# TM4C129ENCPDT register map
File version: 1.0
CPU: CORTEX_M4 1.0, other endian, MPU, FPU, 3 interrupt priority bits
Registers are 32-bit, read-write, reset 0x0 unless marked. A register's access mark holds for its fields unless they carry their own. Offsets are from the block's base; [hi:lo] are bit positions; {n}, {i} and the like mark numbered series.

## EMAC0 — EMAC register offsets
Base 0x400EC000
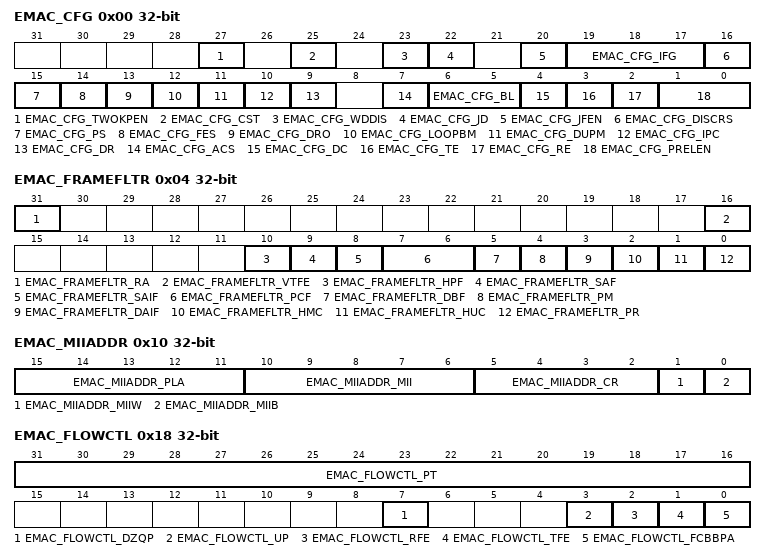
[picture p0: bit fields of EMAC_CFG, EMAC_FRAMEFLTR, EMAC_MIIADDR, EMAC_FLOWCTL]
0x00 EMAC_CFG — Ethernet MAC Configuration
  [27] EMAC_CFG_TWOKPEN — [27:27] IEEE 802
  [25] EMAC_CFG_CST — [25:25] CRC Stripping for Type Frames
  [23] EMAC_CFG_WDDIS — [23:23] Watchdog Disable
  [22] EMAC_CFG_JD — [22:22] Jabber Disable
  [20] EMAC_CFG_JFEN — [20:20] Jumbo Frame Enable
  [19:17] EMAC_CFG_IFG — [19:17] Inter-Frame Gap (IFG)
    0=96 bit times; 0x20000=88 bit times; 0x40000=80 bit times; 0x60000=72 bit times; 0x80000=64 bit times; 0xA0000=56 bit times; 0xC0000=48 bit times; 0xE0000=40 bit times
  [16] EMAC_CFG_DISCRS — [16:16] Disable Carrier Sense During Transmission
  [15] EMAC_CFG_PS — [15:15] Port Select
  [14] EMAC_CFG_FES — [14:14] Speed
  [13] EMAC_CFG_DRO — [13:13] Disable Receive Own
  [12] EMAC_CFG_LOOPBM — [12:12] Loopback Mode
  [11] EMAC_CFG_DUPM — [11:11] Duplex Mode
  [10] EMAC_CFG_IPC — [10:10] Checksum Offload
  [9] EMAC_CFG_DR — [9:9] Disable Retry
  [7] EMAC_CFG_ACS — [7:7] Automatic Pad or CRC Stripping
  [6:5] EMAC_CFG_BL — [6:5] Back-Off Limit
    0=k = min (n,10); 32=k = min (n,8); 64=k = min (n,4); 96=k = min (n,1)
  [4] EMAC_CFG_DC — [4:4] Deferral Check
  [3] EMAC_CFG_TE — [3:3] Transmitter Enable
  [2] EMAC_CFG_RE — [2:2] Receiver Enable
  [1:0] EMAC_CFG_PRELEN — [1:0] Preamble Length for Transmit Frames
    0=7 bytes of preamble; 1=5 bytes of preamble; 2=3 bytes of preamble
0x04 EMAC_FRAMEFLTR — Ethernet MAC Frame Filter
  [31] EMAC_FRAMEFLTR_RA — [31:31] Receive All
  [16] EMAC_FRAMEFLTR_VTFE — [16:16] VLAN Tag Filter Enable
  [10] EMAC_FRAMEFLTR_HPF — [10:10] Hash or Perfect Filter
  [9] EMAC_FRAMEFLTR_SAF — [9:9] Source Address Filter Enable
  [8] EMAC_FRAMEFLTR_SAIF — [8:8] Source Address (SA) Inverse Filtering
  [7:6] EMAC_FRAMEFLTR_PCF — [7:6] Pass Control Frames
    0=EMAC_FRAMEFLTR_PCF_ALL (The MAC filters all control frames from reaching application); 64=EMAC_FRAMEFLTR_PCF_PAUSE (MAC forwards all control frames except PAUSE control frames to application even if they fail the address filter); 128=EMAC_FRAMEFLTR_PCF_NONE (MAC forwards all control frames to application even if they fail the address Filter); 192=EMAC_FRAMEFLTR_PCF_ADDR (MAC forwards control frames that pass the address Filter)
  [5] EMAC_FRAMEFLTR_DBF — [5:5] Disable Broadcast Frames
  [4] EMAC_FRAMEFLTR_PM — [4:4] Pass All Multicast
  [3] EMAC_FRAMEFLTR_DAIF — [3:3] Destination Address (DA) Inverse Filtering
  [2] EMAC_FRAMEFLTR_HMC — [2:2] Hash Multicast
  [1] EMAC_FRAMEFLTR_HUC — [1:1] Hash Unicast
  [0] EMAC_FRAMEFLTR_PR — [0:0] Promiscuous Mode
0x08 EMAC_HASHTBLH — Ethernet MAC Hash Table High
  [31:0] EMAC_HASHTBLH_HTH — [31:0] Hash Table High
0x0C EMAC_HASHTBLL — Ethernet MAC Hash Table Low
  [31:0] EMAC_HASHTBLL_HTL — [31:0] Hash Table Low
0x10 EMAC_MIIADDR — Ethernet MAC MII Address
  [15:11] EMAC_MIIADDR_PLA — [15:11] Physical Layer Address
  [10:6] EMAC_MIIADDR_MII — [10:6] MII Register
  [5:2] EMAC_MIIADDR_CR — [5:2] Clock Reference Frequency Selection
    0=EMAC_MIIADDR_CR_60_100 (The frequency of the System Clock is 60 to 100 MHz providing a MDIO clock of SYSCLK/42); 4=EMAC_MIIADDR_CR_100_150 (The frequency of the System Clock is 100 to 150 MHz providing a MDIO clock of SYSCLK/62); 8=EMAC_MIIADDR_CR_20_35 (The frequency of the System Clock is 20-35 MHz providing a MDIO clock of System Clock/16); 12=EMAC_MIIADDR_CR_35_60 (The frequency of the System Clock is 35 to 60 MHz providing a MDIO clock of System Clock/26)
  [1] EMAC_MIIADDR_MIIW — [1:1] MII Write
  [0] EMAC_MIIADDR_MIIB — [0:0] MII Busy
0x14 EMAC_MIIDATA — Ethernet MAC MII Data Register
  [15:0] EMAC_MIIDATA_DATA — [15:0] MII Data
0x18 EMAC_FLOWCTL — Ethernet MAC Flow Control
  [31:16] EMAC_FLOWCTL_PT — [31:16] Pause Time
  [7] EMAC_FLOWCTL_DZQP — [7:7] Disable Zero-Quanta Pause
  [3] EMAC_FLOWCTL_UP — [3:3] Unicast Pause Frame Detect
  [2] EMAC_FLOWCTL_RFE — [2:2] Receive Flow Control Enable
  [1] EMAC_FLOWCTL_TFE — [1:1] Transmit Flow Control Enable
  [0] EMAC_FLOWCTL_FCBBPA — [0:0] Flow Control Busy or Back-pressure Activate
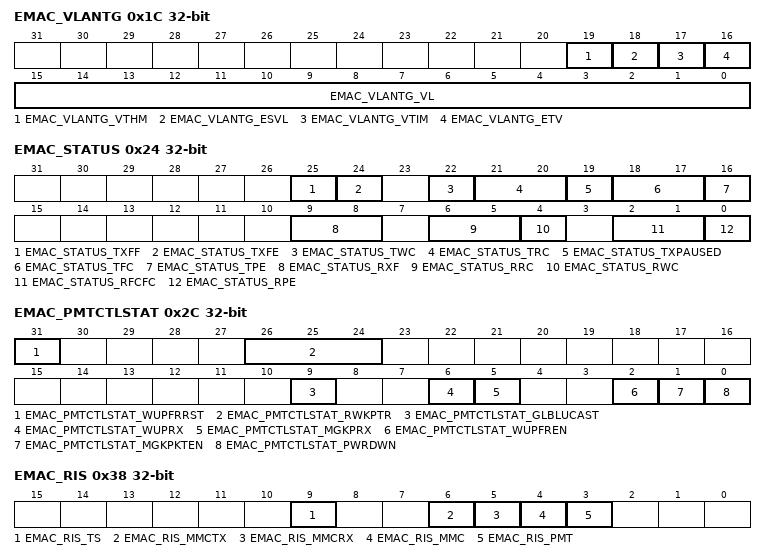
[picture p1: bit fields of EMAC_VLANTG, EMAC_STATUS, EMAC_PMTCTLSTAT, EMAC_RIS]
0x1C EMAC_VLANTG — Ethernet MAC VLAN Tag
  [19] EMAC_VLANTG_VTHM — [19:19] VLAN Tag Hash Table Match Enable
  [18] EMAC_VLANTG_ESVL — [18:18] Enable S-VLAN
  [17] EMAC_VLANTG_VTIM — [17:17] VLAN Tag Inverse Match Enable
  [16] EMAC_VLANTG_ETV — [16:16] Enable 12-Bit VLAN Tag Comparison
  [15:0] EMAC_VLANTG_VL — [15:0] VLAN Tag Identifier for Receive Frames
0x24 EMAC_STATUS — Ethernet MAC Status
  [25] EMAC_STATUS_TXFF — [25:25] TX/RX Controller TX FIFO Full Status
  [24] EMAC_STATUS_TXFE — [24:24] TX/RX Controller TX FIFO Not Empty Status
  [22] EMAC_STATUS_TWC — [22:22] TX/RX Controller TX FIFO Write Controller Active Status
  [21:20] EMAC_STATUS_TRC — [21:20] TX/RX Controller's TX FIFO Read Controller Status
    0=EMAC_STATUS_TRC_IDLE (IDLE state); 0x100000=EMAC_STATUS_TRC_READ (READ state (transferring data to MAC transmitter)); 0x200000=EMAC_STATUS_TRC_WAIT (Waiting for TX Status from MAC transmitter); 0x300000=EMAC_STATUS_TRC_WRFLUSH (Writing the received TX Status or flushing the TX FIFO)
  [19] EMAC_STATUS_TXPAUSED — [19:19] MAC Transmitter PAUSE
  [18:17] EMAC_STATUS_TFC — [18:17] MAC Transmit Frame Controller Status
    0=EMAC_STATUS_TFC_IDLE (IDLE state); 0x20000=EMAC_STATUS_TFC_STATUS (Waiting for status of previous frame or IFG or backoff period to be over); 0x40000=EMAC_STATUS_TFC_PAUSE (Generating and transmitting a PAUSE control frame (in the full-duplex mode)); 0x60000=EMAC_STATUS_TFC_INPUT (Transferring input frame for transmission)
  [16] EMAC_STATUS_TPE — [16:16] MAC MII Transmit Protocol Engine Status
  [9:8] EMAC_STATUS_RXF — [9:8] TX/RX Controller RX FIFO Fill-level Status
    0=EMAC_STATUS_RXF_EMPTY (RX FIFO Empty); 0x100=EMAC_STATUS_RXF_BELOW (RX FIFO fill level is below the flow-control deactivate threshold); 0x200=EMAC_STATUS_RXF_ABOVE (RX FIFO fill level is above the flow-control activate threshold); 0x300=EMAC_STATUS_RXF_FULL (RX FIFO Full)
  [6:5] EMAC_STATUS_RRC — [6:5] TX/RX Controller Read Controller State
    0=EMAC_STATUS_RRC_IDLE (IDLE state); 32=EMAC_STATUS_RRC_STATUS (Reading frame data); 64=EMAC_STATUS_RRC_DATA (Reading frame status (or timestamp)); 96=EMAC_STATUS_RRC_FLUSH (Flushing the frame data and status)
  [4] EMAC_STATUS_RWC — [4:4] TX/RX Controller RX FIFO Write Controller Active Status
  [2:1] EMAC_STATUS_RFCFC — [2:1] MAC Receive Frame Controller FIFO Status
  [0] EMAC_STATUS_RPE — [0:0] MAC MII Receive Protocol Engine Status
0x28 EMAC_RWUFF — Ethernet MAC Remote Wake-Up Frame Filter
  [31:0] EMAC_RWUFF_WAKEUPFIL — [31:0] Remote Wake-Up Frame Filter
0x2C EMAC_PMTCTLSTAT — Ethernet MAC PMT Control and Status Register
  [31] EMAC_PMTCTLSTAT_WUPFRRST — [31:31] Wake-Up Frame Filter Register Pointer Reset
  [26:24] EMAC_PMTCTLSTAT_RWKPTR — [26:24] Remote Wake-Up FIFO Pointer
  [9] EMAC_PMTCTLSTAT_GLBLUCAST — [9:9] Global Unicast
  [6] EMAC_PMTCTLSTAT_WUPRX — [6:6] Wake-Up Frame Received
  [5] EMAC_PMTCTLSTAT_MGKPRX — [5:5] Magic Packet Received
  [2] EMAC_PMTCTLSTAT_WUPFREN — [2:2] Wake-Up Frame Enable
  [1] EMAC_PMTCTLSTAT_MGKPKTEN — [1:1] Magic Packet Enable
  [0] EMAC_PMTCTLSTAT_PWRDWN — [0:0] Power Down
0x38 EMAC_RIS — Ethernet MAC Raw Interrupt Status
  [9] EMAC_RIS_TS — [9:9] Timestamp Interrupt Status
  [6] EMAC_RIS_MMCTX — [6:6] MMC Transmit Interrupt Status
  [5] EMAC_RIS_MMCRX — [5:5] MMC Receive Interrupt Status
  [4] EMAC_RIS_MMC — [4:4] MMC Interrupt Status
  [3] EMAC_RIS_PMT — [3:3] PMT Interrupt Status
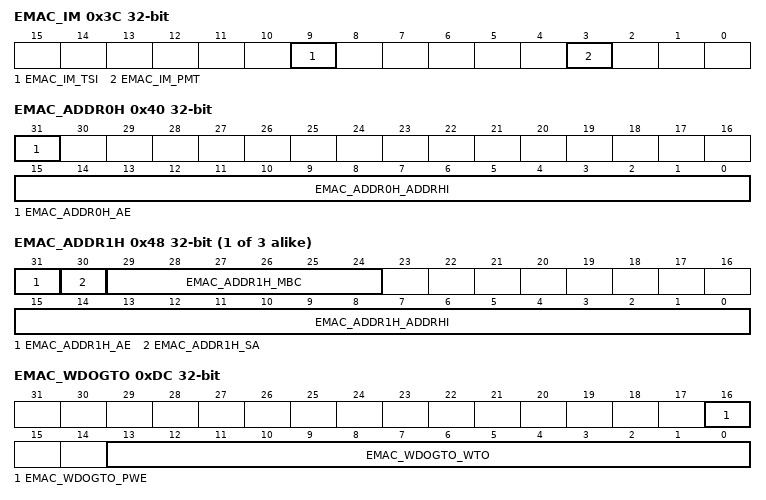
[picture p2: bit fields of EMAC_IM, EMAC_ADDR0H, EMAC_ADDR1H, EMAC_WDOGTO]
0x3C EMAC_IM — Ethernet MAC Interrupt Mask
  [9] EMAC_IM_TSI — [9:9] Timestamp Interrupt Mask
  [3] EMAC_IM_PMT — [3:3] PMT Interrupt Mask
0x40 EMAC_ADDR0H — Ethernet MAC Address 0 High
  [31] EMAC_ADDR0H_AE — [31:31] Address Enable
  [15:0] EMAC_ADDR0H_ADDRHI — [15:0] MAC Address0 [47:32]
0x44 EMAC_ADDR0L — Ethernet MAC Address 0 Low Register
  [31:0] EMAC_ADDR0L_ADDRLO — [31:0] MAC Address0 [31:0]
{0x40+8i} EMAC_ADDR{i}H (i=1..3) — Ethernet MAC Address {i} High
  [31] EMAC_ADDR{i}H_AE — [31:31] Address Enable
  [30] EMAC_ADDR{i}H_SA — [30:30] Source Address
  [29:24] EMAC_ADDR{i}H_MBC — [29:24] Mask Byte Control
  [15:0] EMAC_ADDR{i}H_ADDRHI — [15:0] MAC Address{i} [47:32]
{0x44+8i} EMAC_ADDR{i}L (i=1..3) — Ethernet MAC Address {i} Low
  [31:0] EMAC_ADDR{i}L_ADDRLO — [31:0] MAC Address{i} [31:0]
0xDC EMAC_WDOGTO — Ethernet MAC Watchdog Timeout
  [16] EMAC_WDOGTO_PWE — [16:16] Programmable Watchdog Enable
  [13:0] EMAC_WDOGTO_WTO — [13:0] Watchdog Timeout
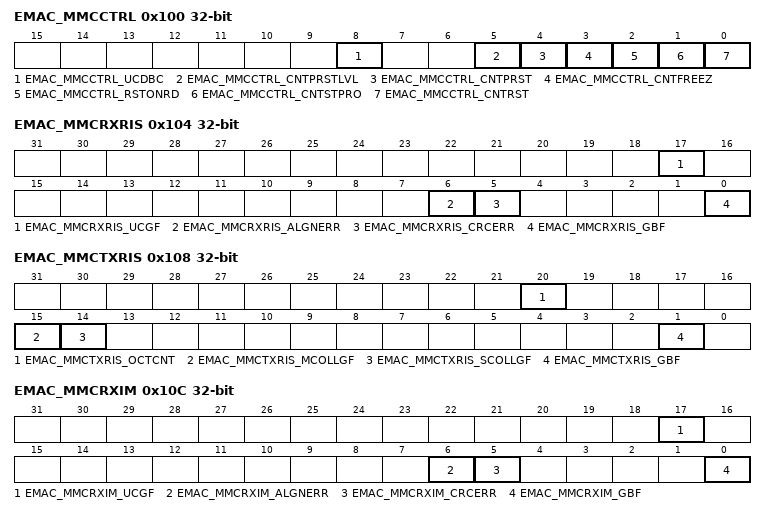
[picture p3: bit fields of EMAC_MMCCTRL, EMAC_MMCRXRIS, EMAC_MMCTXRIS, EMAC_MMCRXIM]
0x100 EMAC_MMCCTRL — Ethernet MAC MMC Control
  [8] EMAC_MMCCTRL_UCDBC — [8:8] Update MMC Counters for Dropped Broadcast Frames
  [5] EMAC_MMCCTRL_CNTPRSTLVL — [5:5] Full/Half Preset Level Value
  [4] EMAC_MMCCTRL_CNTPRST — [4:4] Counters Preset
  [3] EMAC_MMCCTRL_CNTFREEZ — [3:3] MMC Counter Freeze
  [2] EMAC_MMCCTRL_RSTONRD — [2:2] Reset on Read
  [1] EMAC_MMCCTRL_CNTSTPRO — [1:1] Counters Stop Rollover
  [0] EMAC_MMCCTRL_CNTRST — [0:0] Counters Reset
0x104 EMAC_MMCRXRIS — Ethernet MAC MMC Receive Raw Interrupt Status
  [17] EMAC_MMCRXRIS_UCGF — [17:17] MMC Receive Unicast Good Frame Counter Interrupt Status
  [6] EMAC_MMCRXRIS_ALGNERR — [6:6] MMC Receive Alignment Error Frame Counter Interrupt Status
  [5] EMAC_MMCRXRIS_CRCERR — [5:5] MMC Receive CRC Error Frame Counter Interrupt Status
  [0] EMAC_MMCRXRIS_GBF — [0:0] MMC Receive Good Bad Frame Counter Interrupt Status
0x108 EMAC_MMCTXRIS — Ethernet MAC MMC Transmit Raw Interrupt Status
  [20] EMAC_MMCTXRIS_OCTCNT — [20:20] Octet Counter Interrupt Status
  [15] EMAC_MMCTXRIS_MCOLLGF — [15:15] MMC Transmit Multiple Collision Good Frame Counter Interrupt Status
  [14] EMAC_MMCTXRIS_SCOLLGF — [14:14] MMC Transmit Single Collision Good Frame Counter Interrupt Status
  [1] EMAC_MMCTXRIS_GBF — [1:1] MMC Transmit Good Bad Frame Counter Interrupt Status
0x10C EMAC_MMCRXIM — Ethernet MAC MMC Receive Interrupt Mask
  [17] EMAC_MMCRXIM_UCGF — [17:17] MMC Receive Unicast Good Frame Counter Interrupt Mask
  [6] EMAC_MMCRXIM_ALGNERR — [6:6] MMC Receive Alignment Error Frame Counter Interrupt Mask
  [5] EMAC_MMCRXIM_CRCERR — [5:5] MMC Receive CRC Error Frame Counter Interrupt Mask
  [0] EMAC_MMCRXIM_GBF — [0:0] MMC Receive Good Bad Frame Counter Interrupt Mask
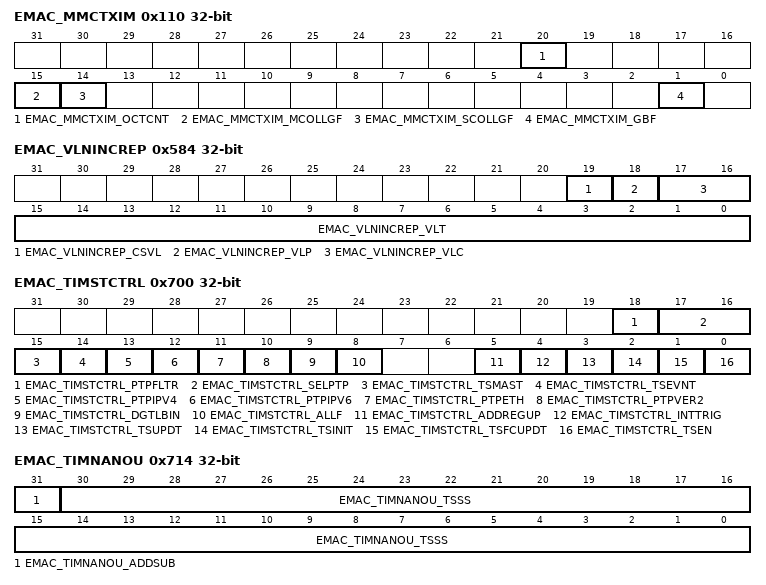
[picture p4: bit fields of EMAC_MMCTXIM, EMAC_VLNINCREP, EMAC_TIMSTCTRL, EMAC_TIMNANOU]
0x110 EMAC_MMCTXIM — Ethernet MAC MMC Transmit Interrupt Mask
  [20] EMAC_MMCTXIM_OCTCNT — [20:20] MMC Transmit Good Octet Counter Interrupt Mask
  [15] EMAC_MMCTXIM_MCOLLGF — [15:15] MMC Transmit Multiple Collision Good Frame Counter Interrupt Mask
  [14] EMAC_MMCTXIM_SCOLLGF — [14:14] MMC Transmit Single Collision Good Frame Counter Interrupt Mask
  [1] EMAC_MMCTXIM_GBF — [1:1] MMC Transmit Good Bad Frame Counter Interrupt Mask
0x118 EMAC_TXCNTGB — Ethernet MAC Transmit Frame Count for Good and Bad Frames
  [31:0] EMAC_TXCNTGB_TXFRMGB — [31:0] This field indicates the number of good and bad frames transmitted, exclusive of retried frames
0x14C EMAC_TXCNTSCOL — Ethernet MAC Transmit Frame Count for Frames Transmitted after Single Collision
  [31:0] EMAC_TXCNTSCOL_TXSNGLCOLG — [31:0] This field indicates the number of successfully transmitted frames after a single collision in the half-duplex mode
0x150 EMAC_TXCNTMCOL — Ethernet MAC Transmit Frame Count for Frames Transmitted after Multiple Collisions
  [31:0] EMAC_TXCNTMCOL_TXMULTCOLG — [31:0] This field indicates the number of successfully transmitted frames after multiple collisions in the half-duplex mode
0x164 EMAC_TXOCTCNTG — Ethernet MAC Transmit Octet Count Good
  [31:0] EMAC_TXOCTCNTG_TXOCTG — [31:0] This field indicates the number of bytes transmitted, exclusive of preamble, in good frames
0x180 EMAC_RXCNTGB — Ethernet MAC Receive Frame Count for Good and Bad Frames
  [31:0] EMAC_RXCNTGB_RXFRMGB — [31:0] This field indicates the number of received good and bad frames
0x194 EMAC_RXCNTCRCERR — Ethernet MAC Receive Frame Count for CRC Error Frames
  [31:0] EMAC_RXCNTCRCERR_RXCRCERR — [31:0] This field indicates the number of frames received with CRC error
0x198 EMAC_RXCNTALGNERR — Ethernet MAC Receive Frame Count for Alignment Error Frames
  [31:0] EMAC_RXCNTALGNERR_RXALGNERR — [31:0] This field indicates the number of frames received with alignment (dribble) error
0x1C4 EMAC_RXCNTGUNI — Ethernet MAC Receive Frame Count for Good Unicast Frames
  [31:0] EMAC_RXCNTGUNI_RXUCASTG — [31:0] This field indicates the number of received good unicast frames
0x584 EMAC_VLNINCREP — Ethernet MAC VLAN Tag Inclusion or Replacement
  [19] EMAC_VLNINCREP_CSVL — [19:19] C-VLAN or S-VLAN
  [18] EMAC_VLNINCREP_VLP — [18:18] VLAN Priority Control
  [17:16] EMAC_VLNINCREP_VLC — [17:16] VLAN Tag Control in Transmit Frames
    0=EMAC_VLNINCREP_VLC_NONE (No VLAN tag deletion, insertion, or replacement); 0x10000=EMAC_VLNINCREP_VLC_TAGDEL (VLAN tag deletion); 0x20000=EMAC_VLNINCREP_VLC_TAGINS (VLAN tag insertion); 0x30000=EMAC_VLNINCREP_VLC_TAGREP (VLAN tag replacement)
  [15:0] EMAC_VLNINCREP_VLT — [15:0] VLAN Tag for Transmit Frames
0x588 EMAC_VLANHASH — Ethernet MAC VLAN Hash Table
  [15:0] EMAC_VLANHASH_VLHT — [15:0] VLAN Hash Table
0x700 EMAC_TIMSTCTRL — Ethernet MAC Timestamp Control
  [18] EMAC_TIMSTCTRL_PTPFLTR — [18:18] Enable MAC address for PTP Frame Filtering
  [17:16] EMAC_TIMSTCTRL_SELPTP — [17:16] Select PTP packets for Taking Snapshots
  [15] EMAC_TIMSTCTRL_TSMAST — [15:15] Enable Snapshot for Messages Relevant to Master
  [14] EMAC_TIMSTCTRL_TSEVNT — [14:14] Enable Timestamp Snapshot for Event Messages
  [13] EMAC_TIMSTCTRL_PTPIPV4 — [13:13] Enable Processing of PTP Frames Sent over IPv4-UDP
  [12] EMAC_TIMSTCTRL_PTPIPV6 — [12:12] Enable Processing of PTP Frames Sent Over IPv6-UDP
  [11] EMAC_TIMSTCTRL_PTPETH — [11:11] Enable Processing of PTP Over Ethernet Frames
  [10] EMAC_TIMSTCTRL_PTPVER2 — [10:10] Enable PTP Packet Processing For Version 2 Format
  [9] EMAC_TIMSTCTRL_DGTLBIN — [9:9] Timestamp Digital or Binary Rollover Control
  [8] EMAC_TIMSTCTRL_ALLF — [8:8] Enable Timestamp For All Frames
  [5] EMAC_TIMSTCTRL_ADDREGUP — [5:5] Addend Register Update
  [4] EMAC_TIMSTCTRL_INTTRIG — [4:4] Timestamp Interrupt Trigger Enable
  [3] EMAC_TIMSTCTRL_TSUPDT — [3:3] Timestamp Update
  [2] EMAC_TIMSTCTRL_TSINIT — [2:2] Timestamp Initialize
  [1] EMAC_TIMSTCTRL_TSFCUPDT — [1:1] Timestamp Fine or Coarse Update
  [0] EMAC_TIMSTCTRL_TSEN — [0:0] Timestamp Enable
0x704 EMAC_SUBSECINC — Ethernet MAC Sub-Second Increment
  [7:0] EMAC_SUBSECINC_SSINC — [7:0] Sub-second Increment Value
0x708 EMAC_TIMSEC — Ethernet MAC System Time - Seconds
  [31:0] EMAC_TIMSEC_TSS — [31:0] Timestamp Second
0x70C EMAC_TIMNANO — Ethernet MAC System Time - Nanoseconds
  [30:0] EMAC_TIMNANO_TSSS — [30:0] Timestamp Sub-Seconds
0x710 EMAC_TIMSECU — Ethernet MAC System Time - Seconds Update
  [31:0] EMAC_TIMSECU_TSS — [31:0] Timestamp Second
0x714 EMAC_TIMNANOU — Ethernet MAC System Time - Nanoseconds Update
  [31] EMAC_TIMNANOU_ADDSUB — [31:31] Add or subtract time
  [30:0] EMAC_TIMNANOU_TSSS — [30:0] Timestamp Sub-Second
0x718 EMAC_TIMADD — Ethernet MAC Timestamp Addend
  [31:0] EMAC_TIMADD_TSAR — [31:0] Timestamp Addend Register
0x71C EMAC_TARGSEC — Ethernet MAC Target Time Seconds
  [31:0] EMAC_TARGSEC_TSTR — [31:0] Target Time Seconds Register
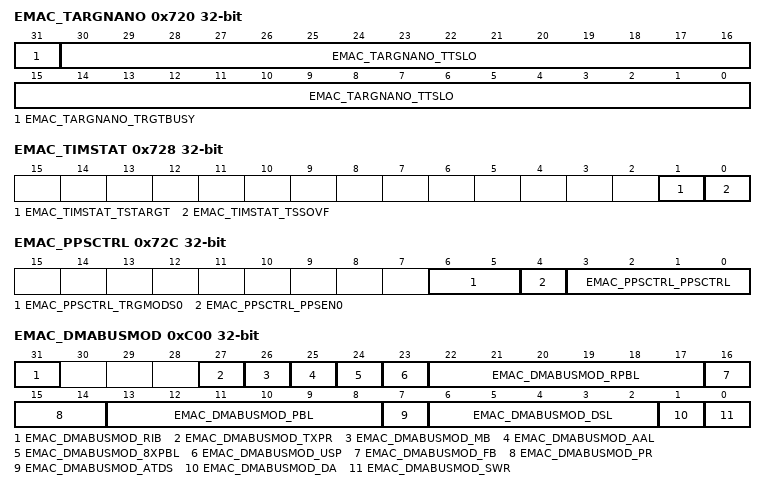
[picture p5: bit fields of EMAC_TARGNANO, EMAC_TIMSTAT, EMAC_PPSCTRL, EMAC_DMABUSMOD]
0x720 EMAC_TARGNANO — Ethernet MAC Target Time Nanoseconds
  [31] EMAC_TARGNANO_TRGTBUSY — [31:31] Target Time Register Busy
  [30:0] EMAC_TARGNANO_TTSLO — [30:0] Target Timestamp Low Register
0x724 EMAC_HWORDSEC — Ethernet MAC System Time-Higher Word Seconds
  [15:0] EMAC_HWORDSEC_TSHWR — [15:0] Target Timestamp Higher Word Register
0x728 EMAC_TIMSTAT — Ethernet MAC Timestamp Status
  [1] EMAC_TIMSTAT_TSTARGT — [1:1] Timestamp Target Time Reached
  [0] EMAC_TIMSTAT_TSSOVF — [0:0] Timestamp Seconds Overflow
0x72C EMAC_PPSCTRL — Ethernet MAC PPS Control
  [6:5] EMAC_PPSCTRL_TRGMODS0 — [6:5] Target Time Register Mode for PPS0 Output
    0=EMAC_PPSCTRL_TRGMODS0_INTONLY (Indicates that the Target Time registers are programmed only for generating the interrupt event); 64=EMAC_PPSCTRL_TRGMODS0_INTPPS0 (Indicates that the Target Time registers are programmed for generating the interrupt event and starting or stopping the generation of the EN0PPS output signal); 96=EMAC_PPSCTRL_TRGMODS0_PPS0ONLY (Indicates that the Target Time registers are programmed only for starting or stopping the generation of the EN0PPS output signal. No interrupt is asserted)
  [4] EMAC_PPSCTRL_PPSEN0 — [4:4] Flexible PPS Output Mode Enable
  [3:0] EMAC_PPSCTRL_PPSCTRL — [3:0] EN0PPS Output Frequency Control (PPSCTRL) or Command Control (PPSCMD)
0x760 EMAC_PPS0INTVL — Ethernet MAC PPS0 Interval
  [31:0] EMAC_PPS0INTVL_PPS0INT — [31:0] PPS0 Output Signal Interval
0x764 EMAC_PPS0WIDTH — Ethernet MAC PPS0 Width
  [31:0] EMAC_PPS0WIDTH — [31:0] EN0PPS Output Signal Width
0xC00 EMAC_DMABUSMOD — Ethernet MAC DMA Bus Mode
  [31] EMAC_DMABUSMOD_RIB — [31:31] Rebuild Burst
  [27] EMAC_DMABUSMOD_TXPR — [27:27] Transmit Priority
  [26] EMAC_DMABUSMOD_MB — [26:26] Mixed Burst
  [25] EMAC_DMABUSMOD_AAL — [25:25] Address Aligned Beats
  [24] EMAC_DMABUSMOD_8XPBL — [24:24] 8 x Programmable Burst Length (PBL) Mode
  [23] EMAC_DMABUSMOD_USP — [23:23] Use Separate Programmable Burst Length (PBL)
  [22:17] EMAC_DMABUSMOD_RPBL — [22:17] RX DMA Programmable Burst Length (PBL)
  [16] EMAC_DMABUSMOD_FB — [16:16] Fixed Burst
  [15:14] EMAC_DMABUSMOD_PR — [15:14] Priority Ratio
  [13:8] EMAC_DMABUSMOD_PBL — [13:8] Programmable Burst Length
  [7] EMAC_DMABUSMOD_ATDS — [7:7] Alternate Descriptor Size
  [6:2] EMAC_DMABUSMOD_DSL — [6:2] Descriptor Skip Length
  [1] EMAC_DMABUSMOD_DA — [1:1] DMA Arbitration Scheme
  [0] EMAC_DMABUSMOD_SWR — [0:0] DMA Software Reset
0xC04 EMAC_TXPOLLD — Ethernet MAC Transmit Poll Demand
  [31:0] EMAC_TXPOLLD_TPD — [31:0] Transmit Poll Demand
0xC08 EMAC_RXPOLLD — Ethernet MAC Receive Poll Demand
  [31:0] EMAC_RXPOLLD_RPD — [31:0] Receive Poll Demand
0xC0C EMAC_RXDLADDR — Ethernet MAC Receive Descriptor List Address
  [31:2] EMAC_RXDLADDR_STRXLIST — [31:2] Start of Receive List
0xC10 EMAC_TXDLADDR — Ethernet MAC Transmit Descriptor List Address
  [31:2] EMAC_TXDLADDR_TXDLADDR — [31:2] Start of Transmit List Base Address
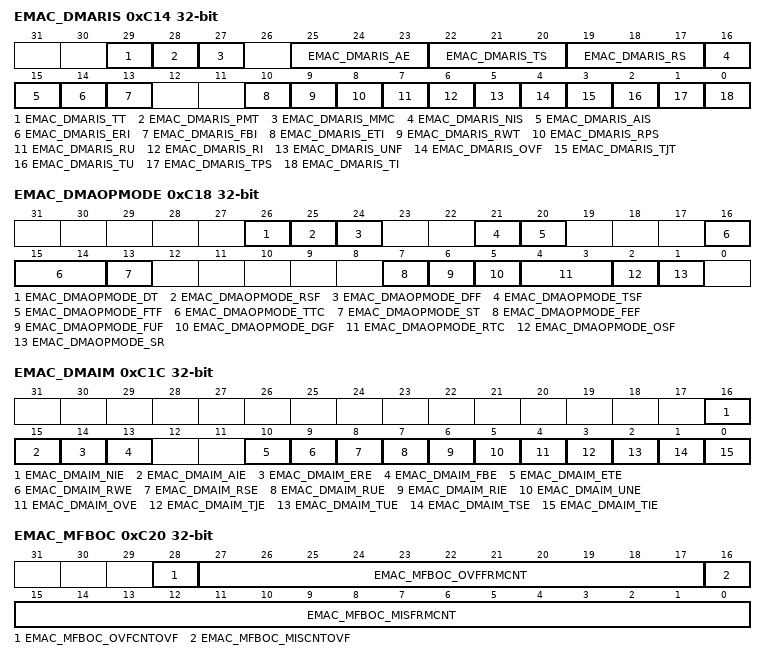
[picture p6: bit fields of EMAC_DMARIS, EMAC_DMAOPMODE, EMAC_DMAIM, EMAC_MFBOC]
0xC14 EMAC_DMARIS — Ethernet MAC DMA Interrupt Status
  [29] EMAC_DMARIS_TT — [29:29] Timestamp Trigger Interrupt Status
  [28] EMAC_DMARIS_PMT — [28:28] MAC PMT Interrupt Status
  [27] EMAC_DMARIS_MMC — [27:27] MAC MMC Interrupt
  [25:23] EMAC_DMARIS_AE — [25:23] Access Error
    0=EMAC_DMARIS_AE_RXDMAWD (Error during RX DMA Write Data Transfer); 0x1800000=EMAC_DMARIS_AE_TXDMARD (Error during TX DMA Read Data Transfer); 0x2000000=EMAC_DMARIS_AE_RXDMADW (Error during RX DMA Descriptor Write Access); 0x2800000=EMAC_DMARIS_AE_TXDMADW (Error during TX DMA Descriptor Write Access); 0x3000000=EMAC_DMARIS_AE_RXDMADR (Error during RX DMA Descriptor Read Access); 0x3800000=EMAC_DMARIS_AE_TXDMADR (Error during TX DMA Descriptor Read Access)
  [22:20] EMAC_DMARIS_TS — [22:20] Transmit Process State
    0=EMAC_DMARIS_TS_STOP (Stopped; Reset or Stop transmit command processed); 0x100000=EMAC_DMARIS_TS_RUNTXTD (Running; Fetching transmit transfer descriptor); 0x200000=EMAC_DMARIS_TS_STATUS (Running; Waiting for status); 0x300000=EMAC_DMARIS_TS_RUNTX (Running; Reading data from host memory buffer and queuing it to transmit buffer (TX FIFO)); 0x400000=EMAC_DMARIS_TS_TSTAMP (Writing Timestamp); 0x600000=EMAC_DMARIS_TS_SUSPEND (Suspended; Transmit descriptor unavailable or transmit buffer underflow); 0x700000=EMAC_DMARIS_TS_RUNCTD (Running; Closing transmit descriptor)
  [19:17] EMAC_DMARIS_RS — [19:17] Received Process State
    0=EMAC_DMARIS_RS_STOP (Stopped: Reset or stop receive command issued); 0x20000=EMAC_DMARIS_RS_RUNRXTD (Running: Fetching receive transfer descriptor); 0x60000=EMAC_DMARIS_RS_RUNRXD (Running: Waiting for receive packet); 0x80000=EMAC_DMARIS_RS_SUSPEND (Suspended: Receive descriptor unavailable); 0xA0000=EMAC_DMARIS_RS_RUNCRD (Running: Closing receive descriptor); 0xC0000=EMAC_DMARIS_RS_TSWS (Writing Timestamp); 0xE0000=EMAC_DMARIS_RS_RUNTXD (Running: Transferring the receive packet data from receive buffer to host memory)
  [16] EMAC_DMARIS_NIS — [16:16] Normal Interrupt Summary
  [15] EMAC_DMARIS_AIS — [15:15] Abnormal Interrupt Summary
  [14] EMAC_DMARIS_ERI — [14:14] Early Receive Interrupt
  [13] EMAC_DMARIS_FBI — [13:13] Fatal Bus Error Interrupt
  [10] EMAC_DMARIS_ETI — [10:10] Early Transmit Interrupt
  [9] EMAC_DMARIS_RWT — [9:9] Receive Watchdog Timeout
  [8] EMAC_DMARIS_RPS — [8:8] Receive Process Stopped
  [7] EMAC_DMARIS_RU — [7:7] Receive Buffer Unavailable
  [6] EMAC_DMARIS_RI — [6:6] Receive Interrupt
  [5] EMAC_DMARIS_UNF — [5:5] Transmit Underflow
  [4] EMAC_DMARIS_OVF — [4:4] Receive Overflow
  [3] EMAC_DMARIS_TJT — [3:3] Transmit Jabber Timeout
  [2] EMAC_DMARIS_TU — [2:2] Transmit Buffer Unavailable
  [1] EMAC_DMARIS_TPS — [1:1] Transmit Process Stopped
  [0] EMAC_DMARIS_TI — [0:0] Transmit Interrupt
0xC18 EMAC_DMAOPMODE — Ethernet MAC DMA Operation Mode
  [26] EMAC_DMAOPMODE_DT — [26:26] Disable Dropping of TCP/IP Checksum Error Frames
  [25] EMAC_DMAOPMODE_RSF — [25:25] Receive Store and Forward
  [24] EMAC_DMAOPMODE_DFF — [24:24] Disable Flushing of Received Frames
  [21] EMAC_DMAOPMODE_TSF — [21:21] Transmit Store and Forward
  [20] EMAC_DMAOPMODE_FTF — [20:20] Flush Transmit FIFO
  [16:14] EMAC_DMAOPMODE_TTC — [16:14] Transmit Threshold Control
    0=64 bytes; 0x4000=128 bytes; 0x8000=192 bytes; 0xC000=256 bytes; 0x10000=40 bytes; 0x14000=32 bytes; 0x18000=24 bytes; 0x1C000=16 bytes
  [13] EMAC_DMAOPMODE_ST — [13:13] Start or Stop Transmission Command
  [7] EMAC_DMAOPMODE_FEF — [7:7] Forward Error Frames
  [6] EMAC_DMAOPMODE_FUF — [6:6] Forward Undersized Good Frames
  [5] EMAC_DMAOPMODE_DGF — [5:5] Drop Giant Frame Enable
  [4:3] EMAC_DMAOPMODE_RTC — [4:3] Receive Threshold Control
    0=64 bytes; 8=32 bytes; 16=96 bytes; 24=128 bytes
  [2] EMAC_DMAOPMODE_OSF — [2:2] Operate on Second Frame
  [1] EMAC_DMAOPMODE_SR — [1:1] Start or Stop Receive
0xC1C EMAC_DMAIM — Ethernet MAC DMA Interrupt Mask Register
  [16] EMAC_DMAIM_NIE — [16:16] Normal Interrupt Summary Enable
  [15] EMAC_DMAIM_AIE — [15:15] Abnormal Interrupt Summary Enable
  [14] EMAC_DMAIM_ERE — [14:14] Early Receive Interrupt Enable
  [13] EMAC_DMAIM_FBE — [13:13] Fatal Bus Error Enable
  [10] EMAC_DMAIM_ETE — [10:10] Early Transmit Interrupt Enable
  [9] EMAC_DMAIM_RWE — [9:9] Receive Watchdog Timeout Enable
  [8] EMAC_DMAIM_RSE — [8:8] Receive Stopped Enable
  [7] EMAC_DMAIM_RUE — [7:7] Receive Buffer Unavailable Enable
  [6] EMAC_DMAIM_RIE — [6:6] Receive Interrupt Enable
  [5] EMAC_DMAIM_UNE — [5:5] Underflow Interrupt Enable
  [4] EMAC_DMAIM_OVE — [4:4] Overflow Interrupt Enable
  [3] EMAC_DMAIM_TJE — [3:3] Transmit Jabber Timeout Enable
  [2] EMAC_DMAIM_TUE — [2:2] Transmit Buffer Unvailable Enable
  [1] EMAC_DMAIM_TSE — [1:1] Transmit Stopped Enable
  [0] EMAC_DMAIM_TIE — [0:0] Transmit Interrupt Enable
0xC20 EMAC_MFBOC — Ethernet MAC Missed Frame and Buffer Overflow Counter
  [28] EMAC_MFBOC_OVFCNTOVF — [28:28] Overflow Bit for FIFO Overflow Counter
  [27:17] EMAC_MFBOC_OVFFRMCNT — [27:17] Overflow Frame Counter
  [16] EMAC_MFBOC_MISCNTOVF — [16:16] Overflow bit for Missed Frame Counter
  [15:0] EMAC_MFBOC_MISFRMCNT — [15:0] Missed Frame Counter
0xC24 EMAC_RXINTWDT — Ethernet MAC Receive Interrupt Watchdog Timer
  [7:0] EMAC_RXINTWDT_RIWT — [7:0] Receive Interrupt Watchdog Timer Count
0xC48 EMAC_HOSTXDESC — Ethernet MAC Current Host Transmit Descriptor
  [31:0] EMAC_HOSTXDESC_CURTXDESC — [31:0] Host Transmit Descriptor Address Pointer
0xC4C EMAC_HOSRXDESC — Ethernet MAC Current Host Receive Descriptor
  [31:0] EMAC_HOSRXDESC_CURRXDESC — [31:0] Host Receive Descriptor Address Pointer
0xC50 EMAC_HOSTXBA — Ethernet MAC Current Host Transmit Buffer Address
  [31:0] EMAC_HOSTXBA_CURTXBUFA — [31:0] Host Transmit Buffer Address Pointer
0xC54 EMAC_HOSRXBA — Ethernet MAC Current Host Receive Buffer Address
  [31:0] EMAC_HOSRXBA_CURRXBUFA — [31:0] Host Receive Buffer Address Pointer
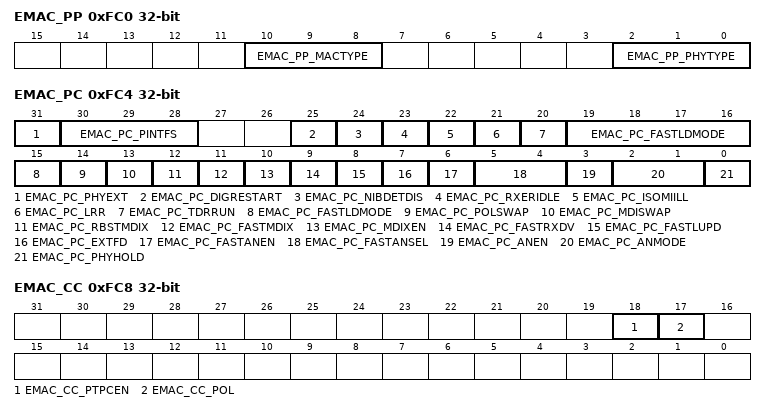
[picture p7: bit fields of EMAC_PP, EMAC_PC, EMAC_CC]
0xFC0 EMAC_PP — Ethernet MAC Peripheral Property Register
  [10:8] EMAC_PP_MACTYPE — [10:8] Ethernet MAC Type
  [2:0] EMAC_PP_PHYTYPE — [2:0] Ethernet PHY Type
    0=EMAC_PP_PHYTYPE_NONE (No PHY); 3=Snowflake class PHY
0xFC4 EMAC_PC — Ethernet MAC Peripheral Configuration Register
  [31] EMAC_PC_PHYEXT — [31:31] PHY Select
  [30:28] EMAC_PC_PINTFS — [30:28] Ethernet Interface Select
    0=EMAC_PC_PINTFS_IMII (MII (default) Used for internal PHY or external PHY connected via MII); 0x40000000=EMAC_PC_PINTFS_RMII (RMII: Used for external PHY connected via RMII)
  [25] EMAC_PC_DIGRESTART — [25:25] PHY Soft Restart
  [24] EMAC_PC_NIBDETDIS — [24:24] Odd Nibble TXER Detection Disable
  [23] EMAC_PC_RXERIDLE — [23:23] RXER Detection During Idle
  [22] EMAC_PC_ISOMIILL — [22:22] Isolate MII in Link Loss
  [21] EMAC_PC_LRR — [21:21] Link Loss Recovery
  [20] EMAC_PC_TDRRUN — [20:20] TDR Auto Run
  [19:15] EMAC_PC_FASTLDMODE — [19:15] Fast Link Down Mode
  [14] EMAC_PC_POLSWAP — [14:14] Polarity Swap
  [13] EMAC_PC_MDISWAP — [13:13] MDI Swap
  [12] EMAC_PC_RBSTMDIX — [12:12] Robust Auto MDI-X
  [11] EMAC_PC_FASTMDIX — [11:11] Fast Auto MDI-X
  [10] EMAC_PC_MDIXEN — [10:10] MDIX Enable
  [9] EMAC_PC_FASTRXDV — [9:9] Fast RXDV Detection
  [8] EMAC_PC_FASTLUPD — [8:8] FAST Link-Up in Parallel Detect
  [7] EMAC_PC_EXTFD — [7:7] Extended Full Duplex Ability
  [6] EMAC_PC_FASTANEN — [6:6] Fast Auto Negotiation Enable
  [5:4] EMAC_PC_FASTANSEL — [5:4] Fast Auto Negotiation Select
  [3] EMAC_PC_ANEN — [3:3] Auto Negotiation Enable
  [2:1] EMAC_PC_ANMODE — [2:1] Auto Negotiation Mode
    0=EMAC_PC_ANMODE_10HD (When ANEN = 0x0, the mode is 10Base-T, Half-Duplex); 2=EMAC_PC_ANMODE_10FD (When ANEN = 0x0, the mode is 10Base-T, Full-Duplex); 4=EMAC_PC_ANMODE_100HD (When ANEN = 0x0, the mode is 100Base-TX, Half-Duplex); 6=EMAC_PC_ANMODE_100FD (When ANEN = 0x0, the mode is 100Base-TX, Full-Duplex)
  [0] EMAC_PC_PHYHOLD — [0:0] Ethernet PHY Hold
0xFC8 EMAC_CC — Ethernet MAC Clock Configuration Register
  [18] EMAC_CC_PTPCEN — [18:18] PTP Clock Reference Enable
  [17] EMAC_CC_POL — [17:17] LED Polarity Control
0xFD0 EMAC_EPHYRIS — Ethernet PHY Raw Interrupt Status
  [0] EMAC_EPHYRIS_INT — [0:0] Ethernet PHY Raw Interrupt Status
0xFD4 EMAC_EPHYIM — Ethernet PHY Interrupt Mask
  [0] EMAC_EPHYIM_INT — [0:0] Ethernet PHY Interrupt Mask
0xFD8 EMAC_EPHYMISC — Ethernet PHY Masked Interrupt Status and Clear
  [0] EMAC_EPHYMISC_INT — [0:0] Ethernet PHY Status and Clear register
